# STM32F30xxx register map
File version: 1.0
Registers are 32-bit, read-write, reset 0x0 unless marked. A register's access mark holds for its fields unless they carry their own. Offsets are from the block's base; [hi:lo] are bit positions; {n}, {i} and the like mark numbered series.

## DAC — Digital-to-analog converter
Base 0x40007400
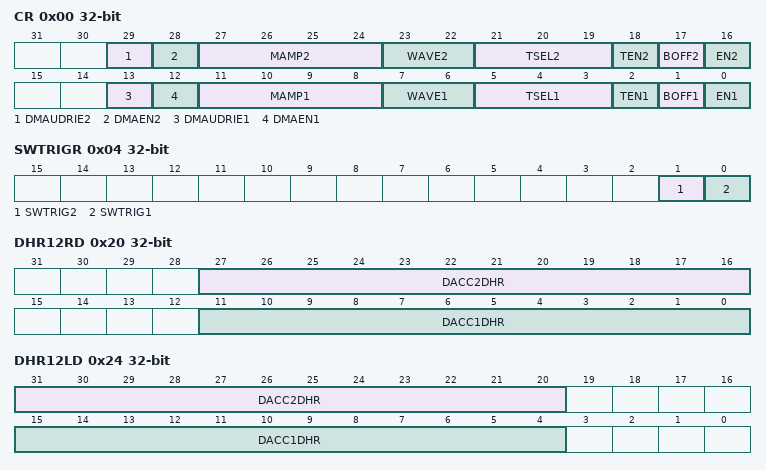
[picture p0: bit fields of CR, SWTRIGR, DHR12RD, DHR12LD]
0x00 CR — control register
  [29] DMAUDRIE2 — DAC channel2 DMA underrun interrupt enable
  [28] DMAEN2 — DAC channel2 DMA enable
  [27:24] MAMP2 — DAC channel2 mask/amplitude selector
  [23:22] WAVE2 — DAC channel2 noise/triangle wave generation enable
  [21:19] TSEL2 — DAC channel2 trigger selection
  [18] TEN2 — DAC channel2 trigger enable
  [17] BOFF2 — DAC channel2 output buffer disable
  [16] EN2 — DAC channel2 enable
  [13] DMAUDRIE1 — DAC channel1 DMA Underrun Interrupt enable
  [12] DMAEN1 — DAC channel1 DMA enable
  [11:8] MAMP1 — DAC channel1 mask/amplitude selector
  [7:6] WAVE1 — DAC channel1 noise/triangle wave generation enable
  [5:3] TSEL1 — DAC channel1 trigger selection
  [2] TEN1 — DAC channel1 trigger enable
  [1] BOFF1 — DAC channel1 output buffer disable
  [0] EN1 — DAC channel1 enable
0x04 SWTRIGR wo — software trigger register
  [1] SWTRIG2 — DAC channel2 software trigger
  [0] SWTRIG1 — DAC channel1 software trigger
0x08 DHR12R1 — channel1 12-bit right-aligned data holding register
  [11:0] DACC1DHR — DAC channel1 12-bit right-aligned data
0x0C DHR12L1 — channel1 12-bit left aligned data holding register
  [15:4] DACC1DHR — DAC channel1 12-bit left-aligned data
0x10 DHR8R1 — channel1 8-bit right aligned data holding register
  [7:0] DACC1DHR — DAC channel1 8-bit right-aligned data
0x14 DHR12R2 — channel2 12-bit right aligned data holding register
  [11:0] DACC2DHR — DAC channel2 12-bit right-aligned data
0x18 DHR12L2 — channel2 12-bit left aligned data holding register
  [15:4] DACC2DHR — DAC channel2 12-bit left-aligned data
0x1C DHR8R2 — channel2 8-bit right-aligned data holding register
  [7:0] DACC2DHR — DAC channel2 8-bit right-aligned data
0x20 DHR12RD — Dual DAC 12-bit right-aligned data holding register
  [27:16] DACC2DHR — DAC channel2 12-bit right-aligned data
  [11:0] DACC1DHR — DAC channel1 12-bit right-aligned data
0x24 DHR12LD — DUAL DAC 12-bit left aligned data holding register
  [31:20] DACC2DHR — DAC channel2 12-bit left-aligned data
  [15:4] DACC1DHR — DAC channel1 12-bit left-aligned data
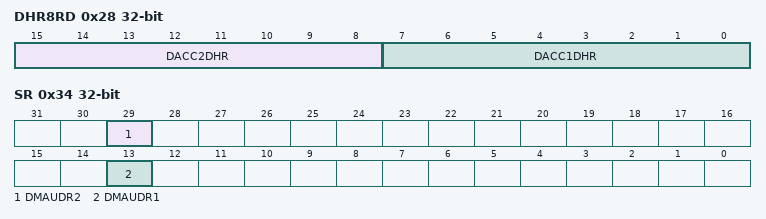
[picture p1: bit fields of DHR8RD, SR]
0x28 DHR8RD — DUAL DAC 8-bit right aligned data holding register
  [15:8] DACC2DHR — DAC channel2 8-bit right-aligned data
  [7:0] DACC1DHR — DAC channel1 8-bit right-aligned data
0x2C DOR1 ro — channel1 data output register
  [11:0] DACC1DOR — DAC channel1 data output
0x30 DOR2 ro — channel2 data output register
  [11:0] DACC2DOR — DAC channel2 data output
0x34 SR — status register
  [29] DMAUDR2 — DAC channel2 DMA underrun flag
  [13] DMAUDR1 — DAC channel1 DMA underrun flag

## NVIC — Nested Vectored Interrupt Controller
Base 0xE000E000
0x00 ICTR ro — Interrupt Controller Type Register
  [3:0] INTLINESNUM — Total number of interrupt lines in groups
0xFC ISERn — Interrupt Set-Enable Registers, ISER0 (0xE000E100) to ISER15 (0xE000E13C)
  [31:0] SETENA
0x17C ICERn — Interrupt Clear-Enable Registers, ICER0 (0xE000E180) to ICER15 (0xE000E1BC)
  [31:0] CLRENA
0x1FC ISPRn — Interrupt Set-Pending Registers, ISPR0 (0xE000E200) to ISPR15 (0xE000E23C)
  [31:0] SETPEND
0x27C ICPRn — Interrupt Clear-Pending Registers, ICPR0 (0xE000E280) to ICPR15 (0xE000E2BC)
  [31:0] CLRPEND
0x2FC IABRn ro — Interrupt Active Bit Registers, IABR0 (0xE000E300) to IABR15 (0xE000E37C)
  [31:0] ACTIVE
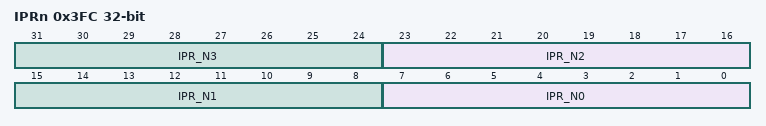
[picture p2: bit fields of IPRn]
0x3FC IPRn — Interrupt Priority Registers, IPR0 (0xE000E400) to IPR123 (0xE000E7EC)
  [8n+7:8n] IPR_N{n} (n=0..3)
0xEFC STIR wo — Software Triggered Interrupt Register
  [8:0] INTID — interrupt to be triggered

## FPU — Floting point unit
Base 0xE000ED88
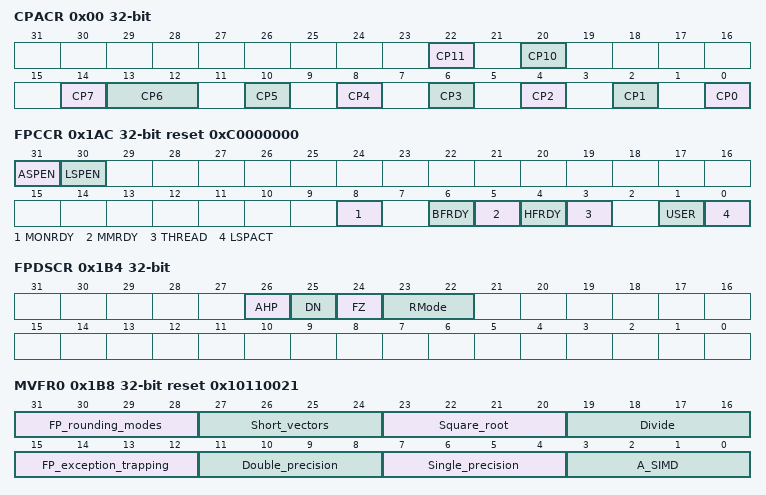
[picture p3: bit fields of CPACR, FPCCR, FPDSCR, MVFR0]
0x00 CPACR — Coprocessor Access Control Register
  [22] CP11 — Access privileges for coprocessor 11
  [20] CP10 — Access privileges for coprocessor 10
  [14] CP7 — Access privileges for coprocessor 7
  [13:12] CP6 — Access privileges for coprocessor 6
  [2n] CP{n} (n=0..5) — Access privileges for coprocessor {n}
0x1AC FPCCR reset 0xC0000000 — FP Context Control Register
  [31] ASPEN, [30] LSPEN, [8] MONRDY, [6] BFRDY, [5] MMRDY, [4] HFRDY, [3] THREAD, [1] USER, [0] LSPACT
0x1B0 FPCAR — FP Context Address Register
  [31:3] ADDRESS
0x1B4 FPDSCR — FP Default Status Control Register
  [26] AHP, [25] DN, [24] FZ, [23:22] RMode
0x1B8 MVFR0 ro reset 0x10110021 — Media and VFP Feature Register 0
  [31:28] FP_rounding_modes
  [27:24] Short_vectors
  [23:20] Square_root
  [19:16] Divide
  [15:12] FP_exception_trapping
  [11:8] Double_precision
  [7:4] Single_precision
  [3:0] A_SIMD — A_SIMD registers
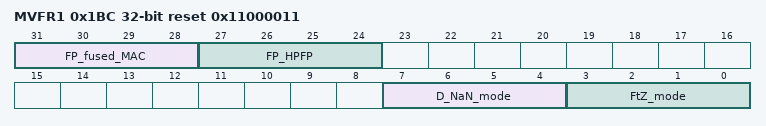
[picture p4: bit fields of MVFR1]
0x1BC MVFR1 ro reset 0x11000011 — Media and VFP Feature Register 1
  [31:28] FP_fused_MAC, [27:24] FP_HPFP, [7:4] D_NaN_mode, [3:0] FtZ_mode
